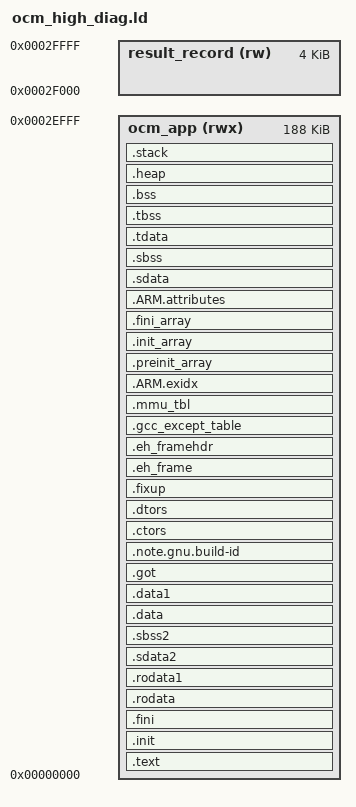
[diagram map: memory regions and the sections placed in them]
_STACK_SIZE = DEFINED(_STACK_SIZE) ? _STACK_SIZE : 0x2000;
_HEAP_SIZE = DEFINED(_HEAP_SIZE) ? _HEAP_SIZE : 0x2000;

_ABORT_STACK_SIZE = DEFINED(_ABORT_STACK_SIZE) ? _ABORT_STACK_SIZE : 1024;
_SUPERVISOR_STACK_SIZE = DEFINED(_SUPERVISOR_STACK_SIZE) ? _SUPERVISOR_STACK_SIZE : 2048;
_IRQ_STACK_SIZE = DEFINED(_IRQ_STACK_SIZE) ? _IRQ_STACK_SIZE : 1024;
_FIQ_STACK_SIZE = DEFINED(_FIQ_STACK_SIZE) ? _FIQ_STACK_SIZE : 1024;
_UNDEF_STACK_SIZE = DEFINED(_UNDEF_STACK_SIZE) ? _UNDEF_STACK_SIZE : 1024;

MEMORY
{
   ocm_app (rwx) : ORIGIN = 0x00000000, LENGTH = 0x0002F000
   result_record (rw) : ORIGIN = 0x0002F000, LENGTH = 0x00001000
}

ENTRY(_vector_table)

SECTIONS
{
.text : {
   . = ALIGN(2048);
   KEEP (*(.vectors))
   *(.boot)
   *(.text)
   *(.text.*)
   *(.gnu.linkonce.t.*)
   *(.plt)
   *(.gnu_warning)
   *(.gcc_execpt_table)
   *(.glue_7)
   *(.glue_7t)
   *(.vfp11_veneer)
   *(.ARM.extab)
   *(.gnu.linkonce.armextab.*)
} > ocm_app

.init : { KEEP (*(.init)) } > ocm_app
.fini : { KEEP (*(.fini)) } > ocm_app

.rodata : {
   __rodata_start = .;
   *(.rodata)
   *(.rodata.*)
   *(.gnu.linkonce.r.*)
   __rodata_end = .;
} > ocm_app

.rodata1 : {
   __rodata1_start = .;
   *(.rodata1)
   *(.rodata1.*)
   __rodata1_end = .;
} > ocm_app

.sdata2 : {
   __sdata2_start = .;
   *(.sdata2)
   *(.sdata2.*)
   *(.gnu.linkonce.s2.*)
   __sdata2_end = .;
} > ocm_app

.sbss2 : {
   __sbss2_start = .;
   *(.sbss2)
   *(.sbss2.*)
   *(.gnu.linkonce.sb2.*)
   __sbss2_end = .;
} > ocm_app

.data : {
   __data_start = .;
   *(.data)
   *(.data.*)
   *(.gnu.linkonce.d.*)
   *(.jcr)
   *(.got)
   *(.got.plt)
   __data_end = .;
} > ocm_app

.data1 : {
   __data1_start = .;
   *(.data1)
   *(.data1.*)
   __data1_end = .;
} > ocm_app

.got : { *(.got) } > ocm_app
.note.gnu.build-id : { KEEP (*(.note.gnu.build-id)) } > ocm_app

.ctors : {
   __CTOR_LIST__ = .;
   ___CTORS_LIST___ = .;
   KEEP (*crtbegin.o(.ctors))
   KEEP (*(EXCLUDE_FILE(*crtend.o) .ctors))
   KEEP (*(SORT(.ctors.*)))
   KEEP (*(.ctors))
   __CTOR_END__ = .;
   ___CTORS_END___ = .;
} > ocm_app

.dtors : {
   __DTOR_LIST__ = .;
   ___DTORS_LIST___ = .;
   KEEP (*crtbegin.o(.dtors))
   KEEP (*(EXCLUDE_FILE(*crtend.o) .dtors))
   KEEP (*(SORT(.dtors.*)))
   KEEP (*(.dtors))
   __DTOR_END__ = .;
   ___DTORS_END___ = .;
} > ocm_app

.fixup : {
   __fixup_start = .;
   *(.fixup)
   __fixup_end = .;
} > ocm_app

.eh_frame : { *(.eh_frame) } > ocm_app
.eh_framehdr : {
   __eh_framehdr_start = .;
   *(.eh_framehdr)
   __eh_framehdr_end = .;
} > ocm_app
.gcc_except_table : { *(.gcc_except_table) } > ocm_app

.mmu_tbl (ALIGN(16384)) : {
   __mmu_tbl_start = .;
   *(.mmu_tbl)
   __mmu_tbl_end = .;
} > ocm_app

.ARM.exidx : {
   __exidx_start = .;
   *(.ARM.exidx*)
   *(.gnu.linkonce.armexidix.*.*)
   __exidx_end = .;
} > ocm_app

.preinit_array : {
   __preinit_array_start = .;
   KEEP (*(SORT(.preinit_array.*)))
   KEEP (*(.preinit_array))
   __preinit_array_end = .;
} > ocm_app

.init_array : {
   __init_array_start = .;
   KEEP (*(SORT(.init_array.*)))
   KEEP (*(.init_array))
   __init_array_end = .;
} > ocm_app

.fini_array : {
   __fini_array_start = .;
   KEEP (*(SORT(.fini_array.*)))
   KEEP (*(.fini_array))
   __fini_array_end = .;
} > ocm_app

.ARM.attributes : {
   __ARM.attributes_start = .;
   *(.ARM.attributes)
   __ARM.attributes_end = .;
} > ocm_app

.sdata : {
   __sdata_start = .;
   *(.sdata)
   *(.sdata.*)
   *(.gnu.linkonce.s.*)
   __sdata_end = .;
} > ocm_app

.sbss (NOLOAD) : {
   __sbss_start = .;
   *(.sbss)
   *(.sbss.*)
   *(.gnu.linkonce.sb.*)
   __sbss_end = .;
} > ocm_app

.tdata : {
   __tdata_start = .;
   *(.tdata)
   *(.tdata.*)
   *(.gnu.linkonce.td.*)
   __tdata_end = .;
} > ocm_app

.tbss : {
   __tbss_start = .;
   *(.tbss)
   *(.tbss.*)
   *(.gnu.linkonce.tb.*)
   __tbss_end = .;
} > ocm_app

.bss (NOLOAD) : {
   __bss_start = .;
   *(.bss)
   *(.bss.*)
   *(.gnu.linkonce.b.*)
   *(COMMON)
   __bss_end = .;
} > ocm_app

_SDA_BASE_ = __sdata_start + ((__sbss_end - __sdata_start) / 2);
_SDA2_BASE_ = __sdata2_start + ((__sbss2_end - __sdata2_start) / 2);

.heap (NOLOAD) : {
   . = ALIGN(16);
   _heap = .;
   HeapBase = .;
   _heap_start = .;
   . += _HEAP_SIZE;
   _heap_end = .;
   HeapLimit = .;
} > ocm_app

.stack (NOLOAD) : {
   . = ALIGN(16);
   _stack_end = .;
   . += _STACK_SIZE;
   . = ALIGN(16);
   _stack = .;
   __stack = _stack;
   . = ALIGN(16);
   _irq_stack_end = .;
   . += _IRQ_STACK_SIZE;
   . = ALIGN(16);
   __irq_stack = .;
   _supervisor_stack_end = .;
   . += _SUPERVISOR_STACK_SIZE;
   . = ALIGN(16);
   __supervisor_stack = .;
   _abort_stack_end = .;
   . += _ABORT_STACK_SIZE;
   . = ALIGN(16);
   __abort_stack = .;
   _fiq_stack_end = .;
   . += _FIQ_STACK_SIZE;
   . = ALIGN(16);
   __fiq_stack = .;
   _undef_stack_end = .;
   . += _UNDEF_STACK_SIZE;
   . = ALIGN(16);
   __undef_stack = .;
} > ocm_app

_end = .;

ASSERT(_end <= ORIGIN(result_record), "OCM application overlaps result record")
}
